# RS1xxxx register map
Vendor: Silicon Lab Inc.; Series: ARMCM4; File version: 1.2
CPU: CM4 r1p0, little endian, MPU, FPU, 6 interrupt priority bits
Registers are 32-bit, read-write, reset 0x0 unless marked. A register's access mark holds for its fields unless they carry their own. Offsets are from the block's base; [hi:lo] are bit positions; lines under a group give offsets from that group; {n}, {i} and the like mark numbered series; 'fields as' and 'values as' point back to an identical list.

## MVP — Matrix Vector Processor Register structure
Base 0x24000000
0x00 MVP_IPVERSION ro reset 0x2
  [31:0] IP_VERSION
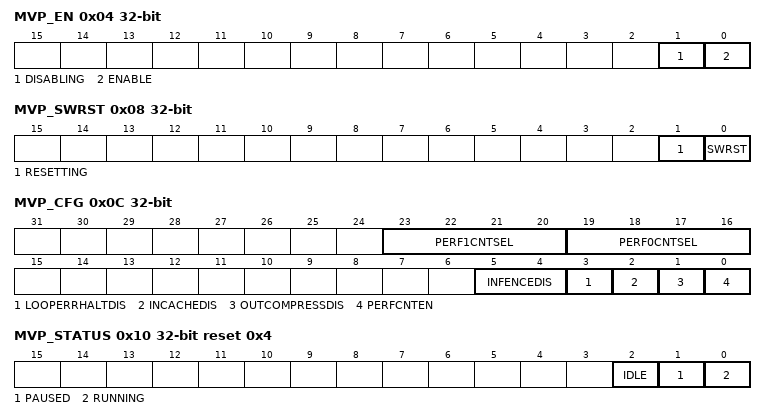
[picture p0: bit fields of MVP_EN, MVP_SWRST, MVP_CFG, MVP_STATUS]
0x04 MVP_EN — Block enable register
  [1] DISABLING ro — Disablement Busy Status
  [0] ENABLE
0x08 MVP_SWRST — software reset register
  [1] RESETTING ro — Software reset busy status
  [0] SWRST wo — Software reset command
0x0C MVP_CFG — configuration register
  [23:20] PERF1CNTSEL — Performence counter select
  [19:16] PERF0CNTSEL — Performence counter select
  [5:4] INFENCEDIS — Fence Disable
  [3] LOOPERRHALTDIS — Loop Error Halt disable
  [2] INCACHEDIS — ALU Input word cache disable
  [1] OUTCOMPRESSDIS — ALU Output stream compression disable
  [0] PERFCNTEN — Performance counter enable
0x10 MVP_STATUS reset 0x4 — Status register
  [2] IDLE ro — Idle Status
  [1] PAUSED ro — Paused Status
  [0] RUNNING ro — Running Status
0x14 MVP_PERF0CNT ro — Run counter
  [23:0] COUNT — Performance counter
0x18 MVP_PERF1CNT ro — Run counter
  [23:0] COUNT — Performance counter
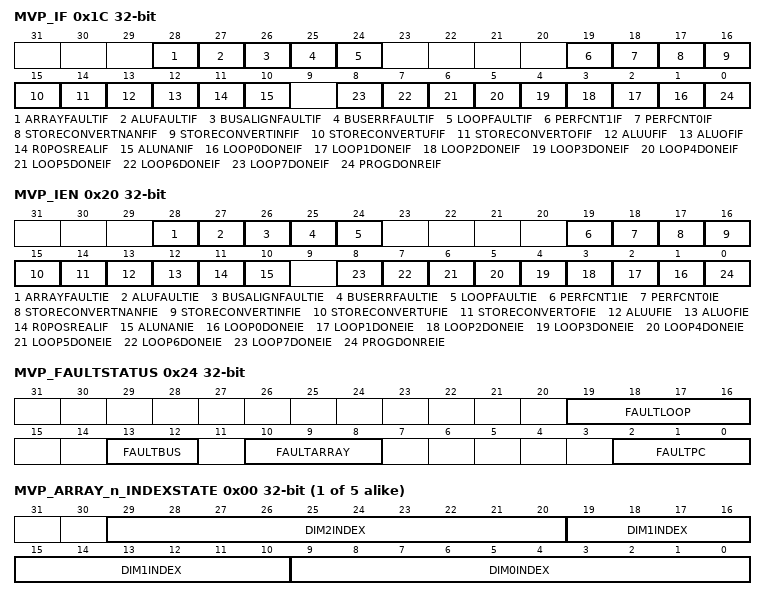
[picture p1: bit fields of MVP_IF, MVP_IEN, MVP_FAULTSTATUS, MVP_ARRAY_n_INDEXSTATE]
0x1C MVP_IF — Interrupt flags
  [28] ARRAYFAULTIF — Array fault interrupt flag
  [27] ALUFAULTIF — ALU Fault fault interrupt flag
  [26] BUSALIGNFAULTIF — Bus error fault interrupt flag
  [25] BUSERRFAULTIF — Bus error fault interrupt flag
  [24] LOOPFAULTIF — Loop Fault interrupt flag
  [19] PERFCNT1IF — Stall count overflow interrupt flag
  [18] PERFCNT0IF — Run count overflow interrupt flag
  [17] STORECONVERTNANFIF — NaN encountered during array store conversion
  [16] STORECONVERTINFIF — Infinity encounterd during array store conversion
  [15] STORECONVERTUFIF — Underflow during array store conversion
  [14] STORECONVERTOFIF — Overflow during array store Conversion
  [13] ALUUFIF — ALU Underflow on result
  [12] ALUOFIF — ALU Overflow on result
  [11] R0POSREALIF — R0 Non Zero interrupt flag
  [10] ALUNANIF — Not A number interrupt flag
  [n+1] LOOP{n}DONEIF (n=0..7) — Loop done interrupt flag
  [0] PROGDONREIF — Programme done interrupt flag
0x20 MVP_IEN — Interrupt Enable
  [28] ARRAYFAULTIE — Array fault interrupt enable
  [27] ALUFAULTIE — ALU Fault fault interrupt flag
  [26] BUSALIGNFAULTIE — Bus error fault interrupt enable
  [25] BUSERRFAULTIE — Bus error fault interrupt enable
  [24] LOOPFAULTIE — Loop Fault interrupt enable
  [19] PERFCNT1IE — Stall count overflow interrupt enable
  [18] PERFCNT0IE — Run count overflow interrupt enable
  [17] STORECONVERTNANFIE — NaN encountered during array store conversion
  [16] STORECONVERTINFIE — store conversion Infinity interrupt enable
  [15] STORECONVERTUFIE — store conversion Underflow interrupt enable
  [14] STORECONVERTOFIE — store Conversion overflow interrupt enable
  [13] ALUUFIE — ALU Underflow Interrupt enable
  [12] ALUOFIE — ALU Overflow Interrupt enable
  [11] R0POSREALIF — R0 Non Zero Interrupt enable
  [10] ALUNANIE — Not a Number interrupt enable
  [n+1] LOOP{n}DONEIE (n=0..7) — Loop done interrupt enable
  [0] PROGDONREIE — Programme done interrupt enable
0x24 MVP_FAULTSTATUS ro — Fault status register
  [19:16] FAULTLOOP — Loop fault indicator
  [13:12] FAULTBUS — Bus when fault occured
  [10:8] FAULTARRAY — Array access that generated a fault
  [2:0] FAULTPC — PC when fault occured
0x28 MVP_FAULTADDR ro — Fault Address register
  [31:0] FAULTADDR — Bus Fault Address Register
0x2C MVP_PROGRAMSTATE — Program state register
  [2:0] PC — Programme Counter
{0x30+4i} MVP_ARRAYnINDEXSTATE[{i}] (i=0..4) group — Array N Index State Registers
  0x00 MVP_ARRAY_n_INDEXSTATE reset not defined — Array _n_ index state register
    [29:20] DIM2INDEX — Current Index
    [19:10] DIM1INDEX — Current Index
    [9:0] DIM0INDEX — Current Index
{0x44+4i} MVP_LOOPnSTATE[{i}] (i=0..7) group — Loop N State Registers
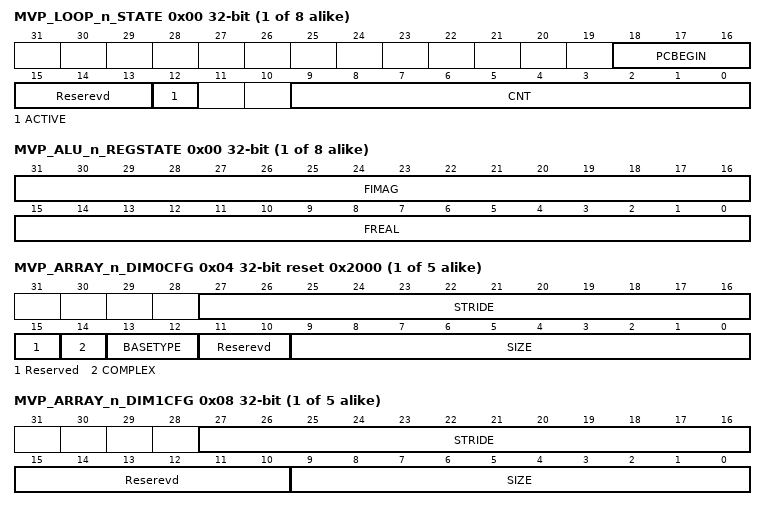
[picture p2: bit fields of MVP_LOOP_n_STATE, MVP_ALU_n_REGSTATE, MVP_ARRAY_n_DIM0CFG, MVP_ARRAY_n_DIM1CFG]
  0x00 MVP_LOOP_n_STATE reset not defined — Loop _n_ state register
    [18:16] PCBEGIN — Loop Start
    [15:13] Reserevd — Reserved
    [12] ACTIVE — Loop Active
    [9:0] CNT — Loop Counter
{0x64+4i} MVP_ALUnREGSTATE[{i}] (i=0..7) group — ALU N Registers State
  0x00 MVP_ALU_n_REGSTATE reset not defined — ALU _n_ register State
    [31:16] FIMAG — Float Imaginary value
    [15:0] FREAL — Float Real value
{0x84+0x10*i} MVP_ARRAYnDIMCFG[{i}] (i=0..4) group — Array N base address and dimension config Registers
  0x00 MVP_ARRAY_n_ADDRCFG reset not defined — Array _n_ base address register
    [31:0] BASE — Array Base Address
  0x04 MVP_ARRAY_n_DIM0CFG reset 0x2000 — Array _n_ Dimension 0 configuration register
    [27:16] STRIDE — Dimension stride step
    [15] Reserved — Reserevd
    [14] COMPLEX — Complex Data Type
    [13:12] BASETYPE — Element Type
    [11:10] Reserevd — Reserved
    [9:0] SIZE — Array Dimesion Size
  0x08 MVP_ARRAY_n_DIM1CFG — Array _n_ Dimension 1 configuration register
    [27:16] STRIDE — Dimension stride step
    [15:10] Reserevd — Reserved
    [9:0] SIZE — Array Dimesion Size
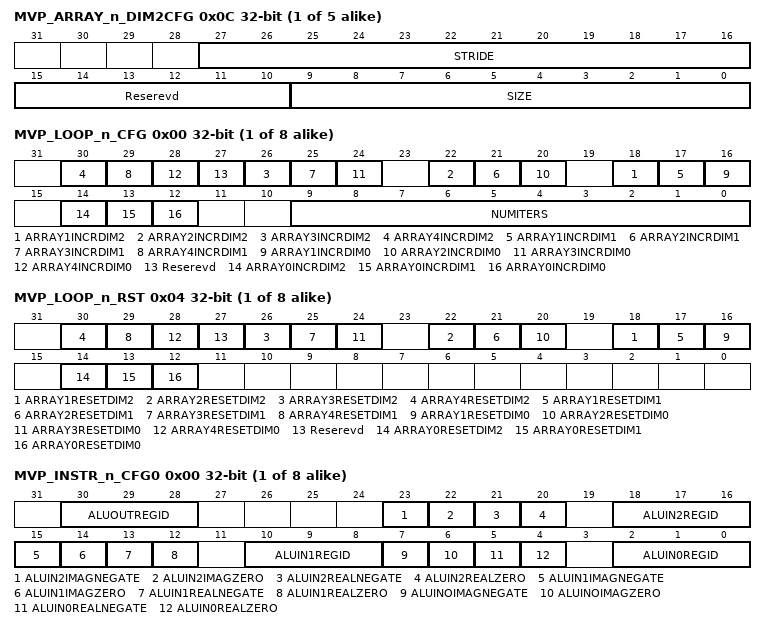
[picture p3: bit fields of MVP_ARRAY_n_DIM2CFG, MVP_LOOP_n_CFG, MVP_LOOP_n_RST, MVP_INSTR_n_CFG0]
  0x0C MVP_ARRAY_n_DIM2CFG — Array _n_ Dimension 2 configuration register
    fields as MVP_ARRAYnDIMCFG[0].MVP_ARRAY_n_DIM1CFG
{0xD4+8i} MVP_LOOPnCFG_RST[{i}] (i=0..7) group — loop N config and reset registers
  0x00 MVP_LOOP_n_CFG reset not defined — Loop _n_ configuration register
    [4n+14] ARRAY{n}INCRDIM2 (n=1..4) — Increment dimension 2
    [4n+13] ARRAY{n}INCRDIM1 (n=1..4) — Increment dimension 1
    [4n+12] ARRAY{n}INCRDIM0 (n=1..4) — Increment dimension 0
    [27] Reserevd — Reserved
    [14] ARRAY0INCRDIM2 — Increment Dimesion 2
    [13] ARRAY0INCRDIM1 — Increment Dimesion 1
    [12] ARRAY0INCRDIM0 — Increment Dimesion 0
    [9:0] NUMITERS — Number of Iterations
  0x04 MVP_LOOP_n_RST reset not defined — Loop _n_ reset configuration register
    [4n+14] ARRAY{n}RESETDIM2 (n=1..4) — Reset dimension 2
    [4n+13] ARRAY{n}RESETDIM1 (n=1..4) — Reset dimension 1
    [4n+12] ARRAY{n}RESETDIM0 (n=1..4) — Reset dimension 0
    [27] Reserevd — Reserved
    [14] ARRAY0RESETDIM2 — Reset Dimesion 2
    [13] ARRAY0RESETDIM1 — Reset Dimesion 1
    [12] ARRAY0RESETDIM0 — Reset Dimesion 0
{0x114+0xC*i} MVP_INSTRnCFG[{i}] (i=0..7) group — Instruction n word 0, 1 ,2,
  0x00 MVP_INSTR_n_CFG0 reset not defined — Instruction _n_ word 0
    [30:28] ALUOUTREGID — Regsiter ID
    [23] ALUIN2IMAGNEGATE — Imaginary Negate
    [22] ALUIN2IMAGZERO — Imaginary Not Zero
    [21] ALUIN2REALNEGATE — Real Negate
    [20] ALUIN2REALZERO — Real Zero
    [18:16] ALUIN2REGID — Register ID
    [15] ALUIN1IMAGNEGATE — Imaginary Negate
    [14] ALUIN1IMAGZERO — Imaginary Not Zero
    [13] ALUIN1REALNEGATE — Real Negate
    [12] ALUIN1REALZERO — Real Zero
    [10:8] ALUIN1REGID — Register ID
    [7] ALUINOIMAGNEGATE — Imaginary Negate
    [6] ALUINOIMAGZERO — Imaginary Not Zero
    [5] ALUIN0REALNEGATE — Real Negate
    [4] ALUIN0REALZERO — Real Zero
    [2:0] ALUIN0REGID — Register Id
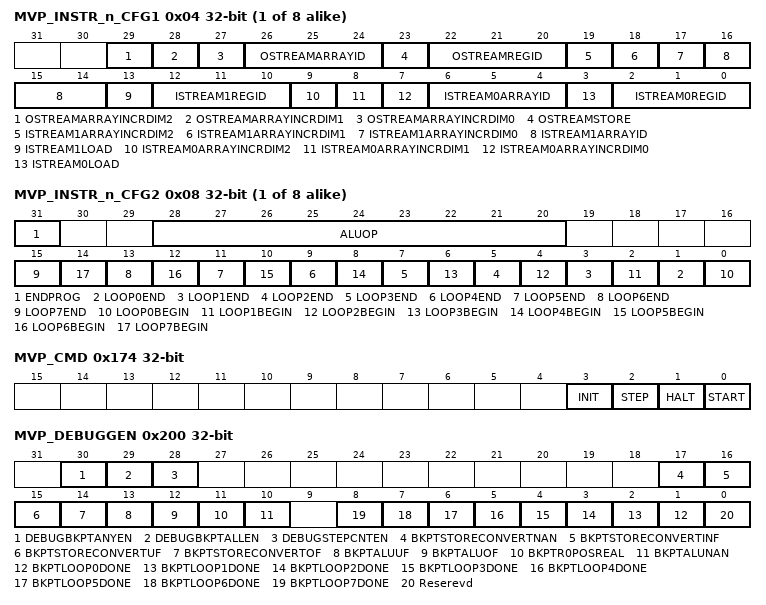
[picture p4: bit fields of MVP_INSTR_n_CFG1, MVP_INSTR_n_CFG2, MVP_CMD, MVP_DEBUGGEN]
  0x04 MVP_INSTR_n_CFG1 reset not defined — Instruction _n_ word 1
    [29] OSTREAMARRAYINCRDIM2 — Increament Array Dimension 2
    [28] OSTREAMARRAYINCRDIM1 — Increament Array Dimension 1
    [27] OSTREAMARRAYINCRDIM0 — Increament Array Dimension 0
    [26:24] OSTREAMARRAYID — Array ID
    [23] OSTREAMSTORE — Store to Register
    [22:20] OSTREAMREGID — Register ID
    [19] ISTREAM1ARRAYINCRDIM2 — Increament Array Dimension 2
    [18] ISTREAM1ARRAYINCRDIM1 — Increament Array Dimension 1
    [17] ISTREAM1ARRAYINCRDIM0 — Increament Array Dimension 0
    [16:14] ISTREAM1ARRAYID — Array ID
    [13] ISTREAM1LOAD — Load Register
    [12:10] ISTREAM1REGID — Register ID
    [9] ISTREAM0ARRAYINCRDIM2 — Increament Array Dimension 2
    [8] ISTREAM0ARRAYINCRDIM1 — Increament Array Dimension 1
    [7] ISTREAM0ARRAYINCRDIM0 — Increament Array Dimension 0
    [6:4] ISTREAM0ARRAYID — Array ID
    [3] ISTREAM0LOAD — Load Register
    [2:0] ISTREAM0REGID — Register Id
  0x08 MVP_INSTR_n_CFG2 reset not defined — Instruction _n_ word 2
    [31] ENDPROG — Reserved
    [28:20] ALUOP — ALU OPcode
    [2n+1] LOOP{n}END (n=0..7) — Loop End
    [2n] LOOP{n}BEGIN (n=0..7) — Loop Begin
0x174 MVP_CMD wo — Command Register
  [3] INIT — Initialization Command/Qualifier
  [2] STEP — Step Command
  [1] HALT — Halt Command
  [0] START — Start Command
0x200 MVP_DEBUGGEN — Debug control register
  [30] DEBUGBKPTANYEN — Trigger Breakpoint when ANY conditions match
  [29] DEBUGBKPTALLEN — Trigger Breakpoint when ALL conditions match
  [28] DEBUGSTEPCNTEN — Debug step count enable
  [17] BKPTSTORECONVERTNAN — Enable breakpoint on STORECONVERTNAN
  [16] BKPTSTORECONVERTINF — Enable breakpoint on STORECONVERTINF
  [15] BKPTSTORECONVERTUF — Enable breakpoint on STORECONVERTUF
  [14] BKPTSTORECONVERTOF — Enable breakpoint on STORECONVERTOF
  [13] BKPTALUUF — Enable breakpoint on ALUUF
  [12] BKPTALUOF — Enable breakpoint on ALUOF
  [11] BKPTR0POSREAL — Enable breakpoint on R0POSREL
  [10] BKPTALUNAN — Enable break point on ALUNAN
  [n+1] BKPTLOOP{n}DONE (n=0..7) — Enable Breakpoint on loop Done
  [0] Reserevd
0x204 MVP_DEBUGSTEPCNT — Debug control register
  [23:0] DEBUGSTEPCNT — Debug Step Counter
0x208 MVP_LOAD0ADDR ro — Cuurent load 0 address
  [31:0] ADDR — Array Address
0x20C MVP_LOAD1ADDR ro — Cuurent load 1 address
  [31:0] ADDR — Array Address
0x210 MVP_STOREADDR ro — Cuurent store address
  [31:0] ADDR — Array Address
